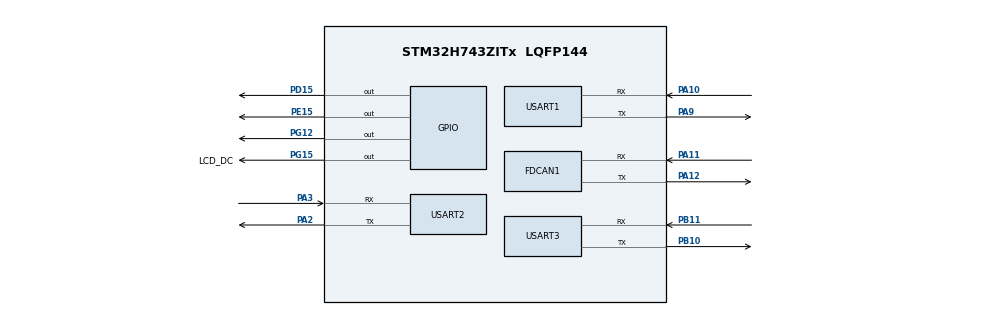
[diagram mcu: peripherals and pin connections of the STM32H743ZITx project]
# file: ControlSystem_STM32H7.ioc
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CORTEX_M7.default_mode_Activation=1
FDCAN1.CalculateBaudRateNominal=500000
FDCAN1.CalculateTimeBitNominal=2000
FDCAN1.CalculateTimeQuantumNominal=125.0
FDCAN1.NominalPrescaler=10
FDCAN1.NominalTimeSeg1=13
FDCAN1.NominalTimeSeg2=2
FDCAN1.RxFifo1ElmtsNbr=0
FDCAN1.TxFifoQueueElmtsNbr=16
FREERTOS.Queues01=MotorDataParseQueue,512,uint8_t,0,Dynamic,NULL,NULL;PressDataParseQueue,512,uint8_t,0,Dynamic,NULL,NULL;IMUDataParseQueue,512,uint8_t,0,Dynamic,NULL,NULL;CmdCtrlQueue,512,uint8_t,0,Dynamic,NULL,NULL
FREERTOS.Tasks01=defaultTask,24,128,StartDefaultTask,As weak,NULL,Dynamic,NULL,NULL;PeriphCtrlTask,8,1024,StartPeriphCtrlTask,As external,NULL,Dynamic,NULL,NULL;DataHandleTask,8,1024,StartDataHandleTask,As external,NULL,Dynamic,NULL,NULL
Mcu.Family=STM32H7
Mcu.Name=STM32H743ZITx
Mcu.Package=LQFP144
NVIC.FDCAN1_IT0_IRQn=true\:5\:0\:false\:false\:true\:true\:true\:true\:true
NVIC.FDCAN1_IT1_IRQn=true\:5\:0\:false\:false\:true\:true\:true\:true\:true
NVIC.FDCAN_CAL_IRQn=true\:5\:0\:false\:false\:true\:true\:true\:true\:true
NVIC.PriorityGroup=NVIC_PRIORITYGROUP_4
NVIC.RCC_IRQn=true\:5\:0\:false\:false\:true\:true\:true\:false\:true
NVIC.TIM2_IRQn=true\:15\:0\:false\:false\:true\:false\:false\:true\:true
NVIC.TimeBase=TIM2_IRQn
NVIC.TimeBaseIP=TIM2
NVIC.USART1_IRQn=true\:5\:0\:false\:false\:true\:true\:true\:true\:true
NVIC.USART2_IRQn=true\:5\:0\:false\:false\:true\:true\:true\:true\:true
NVIC.USART3_IRQn=true\:5\:0\:false\:false\:true\:true\:true\:true\:true
PA10.Mode=Asynchronous
PA10.Signal=USART1_RX
PA11.Mode=FDCAN_Activate
PA11.Signal=FDCAN1_RX
PA12.Mode=FDCAN_Activate
PA12.Signal=FDCAN1_TX
PA13\ (JTMS/SWDIO).Mode=Serial_Wire
PA13\ (JTMS/SWDIO).Signal=DEBUG_JTMS-SWDIO
PA14\ (JTCK/SWCLK).Mode=Serial_Wire
PA14\ (JTCK/SWCLK).Signal=DEBUG_JTCK-SWCLK
PA2.Mode=Asynchronous
PA2.Signal=USART2_TX
PA3.Mode=Asynchronous
PA3.Signal=USART2_RX
PA4.GPIO_Speed=GPIO_SPEED_FREQ_VERY_HIGH
PA4.Signal=DCMI_HSYNC
PA9.Mode=Asynchronous
PA9.Signal=USART1_TX
PB10.Mode=Asynchronous
PB10.Signal=USART3_TX
PB11.Mode=Asynchronous
PB11.Signal=USART3_RX
PD15.GPIO_Speed=GPIO_SPEED_FREQ_VERY_HIGH
PD15.Signal=GPIO_Output
PE15.Signal=GPIO_Output
PF14.Signal=I2C4_SCL
PF15.Signal=I2C4_SDA
PG10.GPIO_Speed=GPIO_SPEED_FREQ_VERY_HIGH
PG10.Signal=DCMI_D2
PG11.GPIO_Speed=GPIO_SPEED_FREQ_VERY_HIGH
PG11.Signal=DCMI_D3
PG12.Signal=GPIO_Output
PG13.GPIO_Speed=GPIO_SPEED_FREQ_VERY_HIGH
PG13.Signal=SPI6_SCK
PG14.GPIO_Speed=GPIO_SPEED_FREQ_VERY_HIGH
PG14.Signal=SPI6_MOSI
PG15.GPIO_Label=LCD_DC
PG15.Signal=GPIO_Output
PG8.Signal=SPI6_NSS
PG9.GPIO_Speed=GPIO_SPEED_FREQ_VERY_HIGH
PG9.Signal=DCMI_VSYNC
PH0-OSC_IN\ (PH0).Mode=HSE-External-Oscillator
PH0-OSC_IN\ (PH0).Signal=RCC_OSC_IN
PH1-OSC_OUT\ (PH1).Mode=HSE-External-Oscillator
PH1-OSC_OUT\ (PH1).Signal=RCC_OSC_OUT
ProjectManager.HeapSize=0x200
ProjectManager.StackSize=0x400
ProjectManager.TargetToolchain=CMake
RCC.ADCFreq_Value=50390625
RCC.APB1Freq_Value=120000000
RCC.APB2Freq_Value=120000000
RCC.APB3Freq_Value=120000000
RCC.APB4Freq_Value=120000000
RCC.CortexFreq_Value=480000000
RCC.D1PPRE=RCC_APB3_DIV2
RCC.D2PPRE1=RCC_APB1_DIV2
RCC.D2PPRE2=RCC_APB2_DIV2
RCC.D3PPRE=RCC_APB4_DIV2
RCC.DIVM1=5
RCC.DIVN1=192
RCC.DIVQ1=12
RCC.HCLKFreq_Value=240000000
RCC.HPRE=RCC_HCLK_DIV2
RCC.PLL2FRACN=0
RCC.PLL3FRACN=0
RCC.PLLFRACN=0
RCC.PLLSourceVirtual=RCC_PLLSOURCE_HSE
RCC.SYSCLKFreq_VALUE=480000000
RCC.SYSCLKSource=RCC_SYSCLKSOURCE_PLLCLK
RCC.USBFreq_Value=80000000
USART1.VirtualMode-Asynchronous=VM_ASYNC
USART2.VirtualMode-Asynchronous=VM_ASYNC
USART3.VirtualMode-Asynchronous=VM_ASYNC
VP_FREERTOS_VS_CMSIS_V2.Mode=CMSIS_V2
VP_MEMORYMAP_VS_MEMORYMAP.Mode=CurAppReg
VP_SYS_VS_tim2.Mode=TIM2
board=custom

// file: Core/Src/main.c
/* USER CODE BEGIN Header */
/**
  ******************************************************************************
  * @file           : main.c
  * @brief          : Main program body
  ******************************************************************************
  * @attention
  *
  * Copyright (c) 2026 STMicroelectronics.
  * All rights reserved.
  *
  * This software is licensed under terms that can be found in the LICENSE file
  * in the root directory of this software component.
  * If no LICENSE file comes with this software, it is provided AS-IS.
  *
  ******************************************************************************
  */
/* USER CODE END Header */
#include "main.h"
#include "cmsis_os.h"
#include "fdcan.h"
#include "usart.h"
#include "gpio.h"

/* USER CODE BEGIN Includes */

#include "usart.h"
// #include "Camera/dcmi_ov5640.h"
#include "Common/can_driver.h"
#include "CR/CR.h"
// #include "Camera/led.h"
#define Camera_Buffer	0x24000000    // 摄像头图像缓冲区
/* USER CODE END Includes */

void SystemClock_Config(void);
static void MPU_Config(void);
void MX_FREERTOS_Init(void);

int main(void)
{

  /* MPU Configuration--------------------------------------------------------*/
  MPU_Config();

  /* MCU Configuration--------------------------------------------------------*/

  /* Reset of all peripherals, Initializes the Flash interface and the Systick. */
  HAL_Init();

  /* Configure the system clock */
  SystemClock_Config();

  /* USER CODE BEGIN SysInit */
  /* Re-configure HAL timebase after clock change (TIM1-based, must be started) */
  HAL_InitTick(TICK_INT_PRIORITY);
  /* USER CODE END SysInit */

  /* Initialize all configured peripherals */
  MX_GPIO_Init();
  MX_USART1_UART_Init();
  MX_USART2_UART_Init();
  MX_USART3_UART_Init();
  MX_FDCAN1_Init();
  /* USER CODE BEGIN 2 */
  CAN_Driver_Init();

  CR_init();
  MPU_Config();

  /* USER CODE END 2 */

  /* Init scheduler */
  osKernelInitialize();  /* Call init function for freertos objects (in cmsis_os2.c) */
  MX_FREERTOS_Init();

  /* Start scheduler */
  osKernelStart();

  /* We should never get here as control is now taken by the scheduler */

  /* Infinite loop */
  while (1)
  {

  }
}

void SystemClock_Config(void)
{
  RCC_OscInitTypeDef RCC_OscInitStruct = {0};
  RCC_ClkInitTypeDef RCC_ClkInitStruct = {0};

  /** Supply configuration update enable
  */
  HAL_PWREx_ConfigSupply(PWR_LDO_SUPPLY);

  /** Configure the main internal regulator output voltage
  */
  __HAL_PWR_VOLTAGESCALING_CONFIG(PWR_REGULATOR_VOLTAGE_SCALE0);

  while(!__HAL_PWR_GET_FLAG(PWR_FLAG_VOSRDY)) {}

  /** Initializes the RCC Oscillators according to the specified parameters
  * in the RCC_OscInitTypeDef structure.
  */
  RCC_OscInitStruct.OscillatorType = RCC_OSCILLATORTYPE_HSE;
  RCC_OscInitStruct.HSEState = RCC_HSE_ON;
  RCC_OscInitStruct.PLL.PLLState = RCC_PLL_ON;
  RCC_OscInitStruct.PLL.PLLSource = RCC_PLLSOURCE_HSE;
  RCC_OscInitStruct.PLL.PLLM = 5;
  RCC_OscInitStruct.PLL.PLLN = 192;
  RCC_OscInitStruct.PLL.PLLP = 2;
  RCC_OscInitStruct.PLL.PLLQ = 12;
  RCC_OscInitStruct.PLL.PLLR = 2;
  RCC_OscInitStruct.PLL.PLLRGE = RCC_PLL1VCIRANGE_2;
  RCC_OscInitStruct.PLL.PLLVCOSEL = RCC_PLL1VCOWIDE;
  RCC_OscInitStruct.PLL.PLLFRACN = 0;
  if (HAL_RCC_OscConfig(&RCC_OscInitStruct) != HAL_OK)
  {
    Error_Handler();
  }

  /** Initializes the CPU, AHB and APB buses clocks
  */
  RCC_ClkInitStruct.ClockType = RCC_CLOCKTYPE_HCLK|RCC_CLOCKTYPE_SYSCLK
                              |RCC_CLOCKTYPE_PCLK1|RCC_CLOCKTYPE_PCLK2
                              |RCC_CLOCKTYPE_D3PCLK1|RCC_CLOCKTYPE_D1PCLK1;
  RCC_ClkInitStruct.SYSCLKSource = RCC_SYSCLKSOURCE_PLLCLK;
  RCC_ClkInitStruct.SYSCLKDivider = RCC_SYSCLK_DIV1;
  RCC_ClkInitStruct.AHBCLKDivider = RCC_HCLK_DIV2;
  RCC_ClkInitStruct.APB3CLKDivider = RCC_APB3_DIV2;
  RCC_ClkInitStruct.APB1CLKDivider = RCC_APB1_DIV2;
  RCC_ClkInitStruct.APB2CLKDivider = RCC_APB2_DIV2;
  RCC_ClkInitStruct.APB4CLKDivider = RCC_APB4_DIV2;

  if (HAL_RCC_ClockConfig(&RCC_ClkInitStruct, FLASH_LATENCY_4) != HAL_OK)
  {
    Error_Handler();
  }
}

 /* MPU Configuration */

void MPU_Config(void)
{
  MPU_Region_InitTypeDef MPU_InitStruct = {0};

  /* Disables the MPU */
  HAL_MPU_Disable();

  /** Initializes and configures the Region and the memory to be protected
  */
  MPU_InitStruct.Enable = MPU_REGION_ENABLE;
  MPU_InitStruct.Number = MPU_REGION_NUMBER0;
  MPU_InitStruct.BaseAddress = 0x0;
  MPU_InitStruct.Size = MPU_REGION_SIZE_4GB;
  MPU_InitStruct.SubRegionDisable = 0x87;
  MPU_InitStruct.TypeExtField = MPU_TEX_LEVEL0;
  MPU_InitStruct.AccessPermission = MPU_REGION_NO_ACCESS;
  MPU_InitStruct.DisableExec = MPU_INSTRUCTION_ACCESS_DISABLE;
  MPU_InitStruct.IsShareable = MPU_ACCESS_SHAREABLE;
  MPU_InitStruct.IsCacheable = MPU_ACCESS_NOT_CACHEABLE;
  MPU_InitStruct.IsBufferable = MPU_ACCESS_NOT_BUFFERABLE;

  HAL_MPU_ConfigRegion(&MPU_InitStruct);
  /* Enables the MPU */
  HAL_MPU_Enable(MPU_PRIVILEGED_DEFAULT);

}

void HAL_TIM_PeriodElapsedCallback(TIM_HandleTypeDef *htim)
{
  if (htim->Instance == TIM2)
  {
    HAL_IncTick();
  }
}

void Error_Handler(void)
{
  __disable_irq();
  while (1)
  {
  }
}
#ifdef USE_FULL_ASSERT
/**
  * @brief  Reports the name of the source file and the source line number
  *         where the assert_param error has occurred.
  * @param  file: pointer to the source file name
  * @param  line: assert_param error line source number
  * @retval None
  */
void assert_failed(uint8_t *file, uint32_t line)
{
  /* USER CODE BEGIN 6 */
  /* User can add his own implementation to report the file name and line number,
     ex: printf("Wrong parameters value: file %s on line %d
", file, line) */
  /* USER CODE END 6 */
}
#endif /* USE_FULL_ASSERT */

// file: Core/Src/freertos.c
/* USER CODE BEGIN Header */
/**
  ******************************************************************************
  * File Name          : freertos.c
  * Description        : Code for freertos applications
  ******************************************************************************
  * @attention
  *
  * Copyright (c) 2026 STMicroelectronics.
  * All rights reserved.
  *
  * This software is licensed under terms that can be found in the LICENSE file
  * in the root directory of this software component.
  * If no LICENSE file comes with this software, it is provided AS-IS.
  *
  ******************************************************************************
  */
/* USER CODE END Header */

#include "FreeRTOS.h"
#include "task.h"
#include "main.h"
#include "cmsis_os.h"

/* USER CODE BEGIN Includes */
#include "usart.h"
/* USER CODE END Includes */

/* Definitions for defaultTask */
osThreadId_t defaultTaskHandle;
const osThreadAttr_t defaultTask_attributes = {
  .name = "defaultTask",
  .stack_size = 128 * 4,
  .priority = (osPriority_t) osPriorityNormal,
};
/* Definitions for PeriphCtrlTask */
osThreadId_t PeriphCtrlTaskHandle;
const osThreadAttr_t PeriphCtrlTask_attributes = {
  .name = "PeriphCtrlTask",
  .stack_size = 1024 * 4,
  .priority = (osPriority_t) osPriorityLow,
};
/* Definitions for DataHandleTask */
osThreadId_t DataHandleTaskHandle;
const osThreadAttr_t DataHandleTask_attributes = {
  .name = "DataHandleTask",
  .stack_size = 1024 * 4,
  .priority = (osPriority_t) osPriorityLow,
};
/* Definitions for MotorDataParseQueue */
osMessageQueueId_t MotorDataParseQueueHandle;
const osMessageQueueAttr_t MotorDataParseQueue_attributes = {
  .name = "MotorDataParseQueue"
};
/* Definitions for PressDataParseQueue */
osMessageQueueId_t PressDataParseQueueHandle;
const osMessageQueueAttr_t PressDataParseQueue_attributes = {
  .name = "PressDataParseQueue"
};
/* Definitions for IMUDataParseQueue */
osMessageQueueId_t IMUDataParseQueueHandle;
const osMessageQueueAttr_t IMUDataParseQueue_attributes = {
  .name = "IMUDataParseQueue"
};
/* Definitions for CmdCtrlQueue */
osMessageQueueId_t CmdCtrlQueueHandle;
const osMessageQueueAttr_t CmdCtrlQueue_attributes = {
  .name = "CmdCtrlQueue"
};

void StartDefaultTask(void *argument);
extern void StartPeriphCtrlTask(void *argument);
extern void StartDataHandleTask(void *argument);

void MX_FREERTOS_Init(void); /* (MISRA C 2004 rule 8.1) */

void MX_FREERTOS_Init(void) {

  /* Create the queue(s) */
  /* creation of MotorDataParseQueue */
  MotorDataParseQueueHandle = osMessageQueueNew (256 * 8, sizeof(uint8_t), &MotorDataParseQueue_attributes);

  /* creation of PressDataParseQueue */
  PressDataParseQueueHandle = osMessageQueueNew (256 * 8, sizeof(uint8_t), &PressDataParseQueue_attributes);

  /* creation of IMUDataParseQueue */
  IMUDataParseQueueHandle = osMessageQueueNew (256 * 8, sizeof(uint8_t), &IMUDataParseQueue_attributes);

  /* creation of CmdCtrlQueue */
  CmdCtrlQueueHandle = osMessageQueueNew (256 * 8, sizeof(uint8_t), &CmdCtrlQueue_attributes);

  /* Create the thread(s) */
  /* creation of defaultTask */
  defaultTaskHandle = osThreadNew(StartDefaultTask, NULL, &defaultTask_attributes);

  /* creation of PeriphCtrlTask */
  PeriphCtrlTaskHandle = osThreadNew(StartPeriphCtrlTask, NULL, &PeriphCtrlTask_attributes);

  /* creation of DataHandleTask */
  DataHandleTaskHandle = osThreadNew(StartDataHandleTask, NULL, &DataHandleTask_attributes);

}

__weak void StartDefaultTask(void *argument)
{
  /* USER CODE BEGIN StartDefaultTask */
  UART_Receive_Init();

  /* Raw UART write to verify task entry, no HAL dependency */
  { volatile uint32_t *tdr = (volatile uint32_t *)0x40011028; volatile uint32_t *isr = (volatile uint32_t *)0x4001101C; while (!(*isr & 0x80)) {} *tdr = 'D'; for(volatile int __d=0;__d<100000;__d++){} }
  HAL_GPIO_TogglePin(GPIOG, GPIO_PIN_7);

  /* Infinite loop */
  for(;;)
  {
    osDelay(1);
  }
  /* USER CODE END StartDefaultTask */
}
